# APM32F446 register map
File version: 1.0
CPU: CM4 r0p1, little endian, MPU, FPU, 4 interrupt priority bits
Registers are 32-bit, read-write, reset 0x0 unless marked. A register's access mark holds for its fields unless they carry their own. Offsets are from the block's base; [hi:lo] are bit positions; 'fields as' and 'values as' point back to an identical list.

## MSC — Miscellaneous System Control
Base 0x40001000
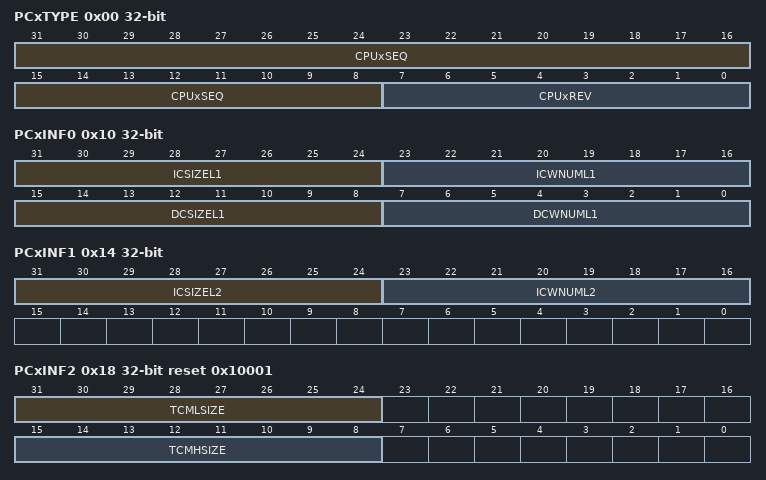
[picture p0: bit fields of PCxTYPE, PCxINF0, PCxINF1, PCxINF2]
0x00 PCxTYPE ro reset not defined — Processor X Type Register
  [31:8] CPUxSEQ — CPUx Processor Specific Sequence
  [7:0] CPUxREV — CPUx Processor Revision
0x04 CPUxLPNUM ro (reset mask 0xFFFFFFFE) — CPUx Logical Processor Number Register
  [0] CPUxLPNUM — CPUx Logical Processor Number
0x08 CPUxPBMNUM ro (reset mask 0xFFFFFFC0) — CPUx Physical Bus Master Number Register
  [5:0] CPUxPBMNUM — CPUx Physical Bus Master Number
0x0C CPUxCNT ro — CPUx Count Register
  [1:0] PCNT — Processor Count
0x10 PCxINF0 ro reset not defined — Processor X Information Register 0
  [31:24] ICSIZEL1 — Level 1 Instruction Cache Size
  [23:16] ICWNUML1 — Number of Level 1 Instruction Cache Way
  [15:8] DCSIZEL1 — Level 1 Data Cache Size
  [7:0] DCWNUML1 — Number of Level 1 Data Cache Way
0x14 PCxINF1 ro (reset mask 0xFFFF) — Processor X Information Register 1
  [31:24] ICSIZEL2 — Level 2 Instruction Cache Size
  [23:16] ICWNUML2 — Number of Level 2 Instruction Cache Way
0x18 PCxINF2 ro reset 0x10001 (reset mask 0xFF00FF) — Processor X Information Register 2
  [31:24] TCMLSIZE — Tightly-Coupled Memory Lower Size
  [15:8] TCMHSIZE — Tightly-Coupled Memory Higher Size
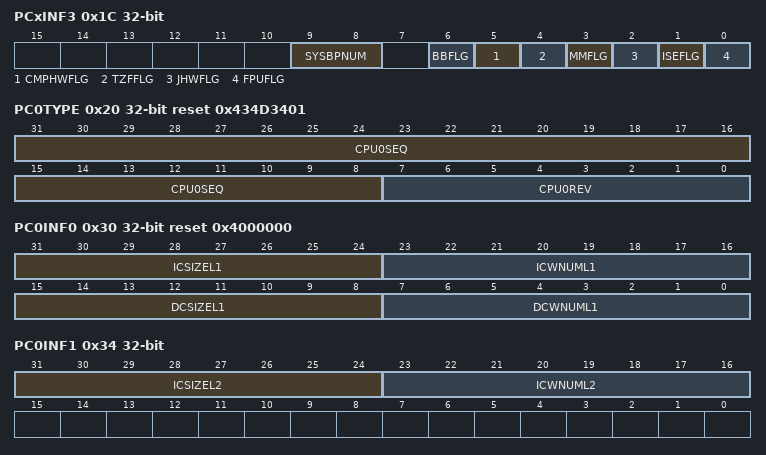
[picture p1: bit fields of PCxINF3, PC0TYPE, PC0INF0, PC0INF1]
0x1C PCxINF3 ro (reset mask 0xFFFFFC80) — Processor X Information Register 3
  [9:8] SYSBPNUM — Number of System Bus Ports
  [6] BBFLG — Support Bit Banding Flag
    0=Bit Banding is not supported; 1=Bit Banding is supported
  [5] CMPHWFLG — Support Core Memory Protection Hardware Flag
    0=Core Memory Protection is not included; 1=Core Memory Protection is included
  [4] TZFFLG — Support Trust Zone Function Flag
    0=Trust Zone support is not included; 1=Trust Zone support is included
  [3] MMFLG — Support Memory Management Unit Flag
    0=MMU support is not included; 1=MMU support is included
  [2] JHWFLG — Support Jazelle Hardware Flag
    0=Jazelle support is not included; 1=Jazelle support is included
  [1] ISEFLG — Support Instruction Set Extension
    0=SIMD/NEON support is not included; 1=SIMD/NEON support is included
  [0] FPUFLG — Support Floating Point Unit Flag
    0=FPU support is not included; 1=FPU support is included
0x20 PC0TYPE ro reset 0x434D3401 — Processor 0 Type Register
  [31:8] CPU0SEQ — CPU0 Processor Specific Sequence
  [7:0] CPU0REV — CPU0 Processor Revision
0x24 CPU0LPNUM ro — CPU0 Logical Processor Number Register
  [0] CPU0LPNUM — Processor 0 Number
0x28 CPU0PBNUM ro — CPU0 Physical Bus Master Number Register
  [5:0] CPU0PBMNUM — CPU0 Physical Bus Master Number
0x2C CPU0CNT ro — CPU0 Count Register
  [1:0] PCNT — Processor Count
0x30 PC0INF0 ro reset 0x4000000 — Processor 0 Information Register 0
  fields as PCxINF0
0x34 PC0INF1 ro — Processor 0 Information Register 1
  fields as PCxINF1
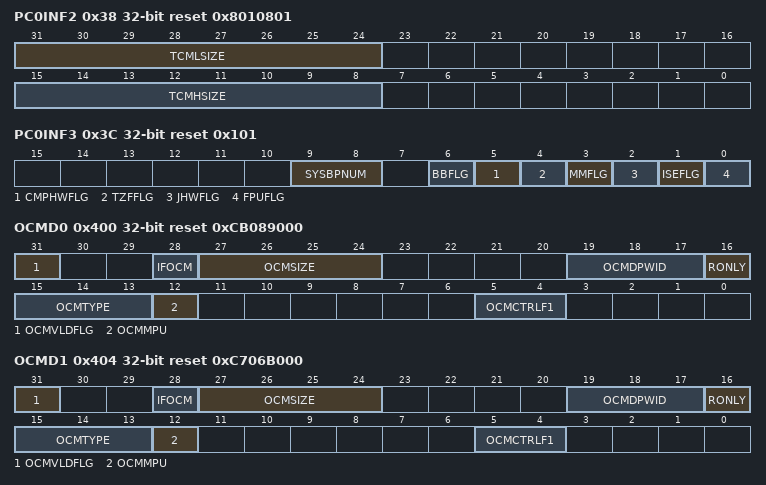
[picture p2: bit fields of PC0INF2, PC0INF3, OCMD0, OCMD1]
0x38 PC0INF2 ro reset 0x8010801 — Processor 0 Information Register 2
  fields as PCxINF2
0x3C PC0INF3 ro reset 0x101 — Processor 0 Information Register 3
  fields as PCxINF3
0x400 OCMD0 reset 0xCB089000 — On-Chip Memory Descriptor Register 0
  [31] OCMVLDFLG ro — On-Chip Memory Valid Flag
    0=OCMEMn is not present; 1=OCMEMn is present
  [28] IFOCM ro — Incompletely Filled On-Chip Memory
    0=OCMEMn is a power-of-2 capacity; 1=OCMEMn is not a power-of-2, with a capacity is 0.75 * OCMSZ
  [27:24] OCMSIZE ro — On-Chip Memory Size
    0=no OCMEMn; 1=1KB OCMEMn; 2=2KB OCMEMn; 3=4KB OCMEMn; 4=8KB OCMEMn; 5=16KB OCMEMn; 6=32KB OCMEMn; 7=64KB OCMEMn; 8=128KB OCMEMn; 9=256KB OCMEMn; 10=512KB OCMEMn; 11=1MB OCMEMn; 12=2MB OCMEMn; 13=4MB OCMEMn; 14=8MB OCMEMn; 15=16MB OCMEMn
  [19:17] OCMDPWID ro — On-Chip Memory Datapath Width
    2=OCMEMn 32-bits wide; 3=OCMEMn 64-bits wide; 4=OCMEMn 128-bits wide; 5=OCMEMn 256-bits wide
  [16] RONLY — Read-Only
    0=Writes to the OCMDn[11:0] are allowed; 1=Writes to the OCMDn[11:0] are ignored
  [15:13] OCMTYPE ro — On-Chip Memory Type
    4=OCMEMn is a Program Flash; 5=OCMEMn is a Data Flash; 6=OCMEMn is an EEE
  [12] OCMMPU ro — On-Chip Memory Memory Protect Unit
  [5:4] OCMCTRLF1 — On-Chip Memory Control Field 1
0x404 OCMD1 reset 0xC706B000 — On-Chip Memory Descriptor Register 1
  fields as OCMD0
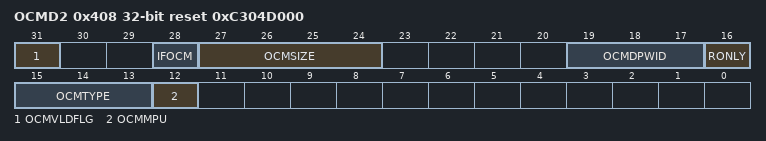
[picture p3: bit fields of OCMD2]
0x408 OCMD2 reset 0xC304D000 — On-Chip Memory Descriptor Register2
  [31] OCMVLDFLG ro — On-Chip Memory Valid Flag
    0=OCMEMn is not present; 1=OCMEMn is present
  [28] IFOCM ro — Incompletely Filled On-Chip Memory
    values as OCMD0.IFOCM
  [27:24] OCMSIZE ro — On-Chip Memory Size
    values as OCMD0.OCMSIZE
  [19:17] OCMDPWID ro — On-Chip Memory Datapath Width
    values as OCMD0.OCMDPWID
  [16] RONLY — Read-Only
    values as OCMD0.RONLY
  [15:13] OCMTYPE ro — On-Chip Memory Type
    values as OCMD0.OCMTYPE
  [12] OCMMPU ro — On-Chip Memory Memory Protect Unit
